# EFR32FG23B010F512IM48 register map
Vendor: Silicon Labs; Series: EFR32; File version: C
CPU: CM33 r0p4, little endian, MPU, FPU, DSP, VTOR, 4 interrupt priority bits, 8 SAU regions
Registers are 32-bit, read-write, reset 0x0 unless marked. A register's access mark holds for its fields unless they carry their own. Offsets are from the block's base; [hi:lo] are bit positions; {n}, {i} and the like mark numbered series.

## LCDRF_NS — LCDRF_NS Registers
Base 0x500C0000
Same registers: LCDRF_S 0x400C0000
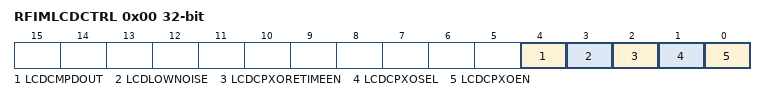
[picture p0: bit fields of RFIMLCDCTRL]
0x00 RFIMLCDCTRL
  [4] LCDCMPDOUT — LCD Comparator Dout
  [3] LCDLOWNOISE
    0=NORMAL (Normal operation); 1=SLOW (slows down slew rate to reduce RF interference at a cost of additional power consumption)
  [2] LCDCPXORETIMEEN — LCD Charge Pump XO Retime Enable
  [1] LCDCPXOSEL — LCD Charge Pump XO Select
    0=INTRCO (Internal LCD CP 10Mhz RC oscillator); 1=HFXODIV (HFXO divided 4 clock)
  [0] LCDCPXOEN — LCD Charge Pump XO Clock Enable

## LDMAXBAR_NS — LDMAXBAR_NS Registers
Base 0x50044000
Same registers: LDMAXBAR_S 0x40044000
0x00 IPVERSION ro reset 0x2
  [31:0] IPVERSION — IP Version ID
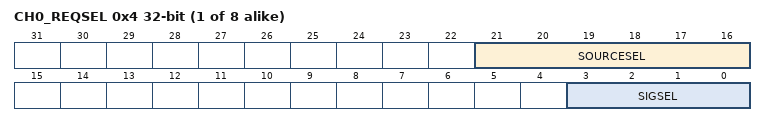
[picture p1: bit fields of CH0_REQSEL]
{0x4+4i} CH{i}_REQSEL (i=0..7)
  [21:16] SOURCESEL — Source Select
  [3:0] SIGSEL — Signal Select

## LFRCO_NS — LFRCO_NS Registers
Base 0x50024000
Same registers: LFRCO_S 0x40024000
0x00 IPVERSION ro — Contains the LFRCO ip version.
  [31:0] IPVERSION — IP version ID
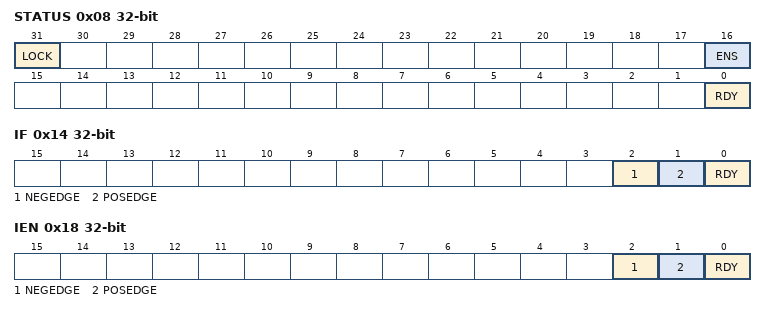
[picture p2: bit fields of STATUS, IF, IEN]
0x08 STATUS ro
  [31] LOCK — Lock Status
    0=UNLOCKED (Access to configuration registers not locked); 1=LOCKED (Access to configuration registers locked)
  [16] ENS — Enabled Status
  [0] RDY — Ready Status
0x0C CAL reset 0xA5 — Calibration register
  [7:0] FREQTRIM — Frequency Trim
0x14 IF — Interrupt flag register
  [2] NEGEDGE — Falling Edge Interrupt Flag
  [1] POSEDGE — Rising Edge Interrupt Flag
  [0] RDY — Ready Interrupt Flag
0x18 IEN — Interrupt enable register.
  [2] NEGEDGE — Falling Edge Interrupt Enable
  [1] POSEDGE — Rising Edge Interrupt Enable
  [0] RDY — Ready Interrupt Enable
0x1C SYNCBUSY ro — Synchronization busy register
  [0] CAL — CAL Busy
0x20 LOCK wo reset 0x2603 — Configuration lock register. Locks/unlocks access to cofiguration registers.
  [15:0] LOCKKEY
    0=LOCK (Lock Configuration Registers); 0x2603=UNLOCK (Unlock Configuaration Registers)

## LFXO_NS — LFXO_NS Registers
Base 0x50020000
Same registers: LFXO_S 0x40020000
0x00 IPVERSION ro
  [31:0] IPVERSION — IP Version ID
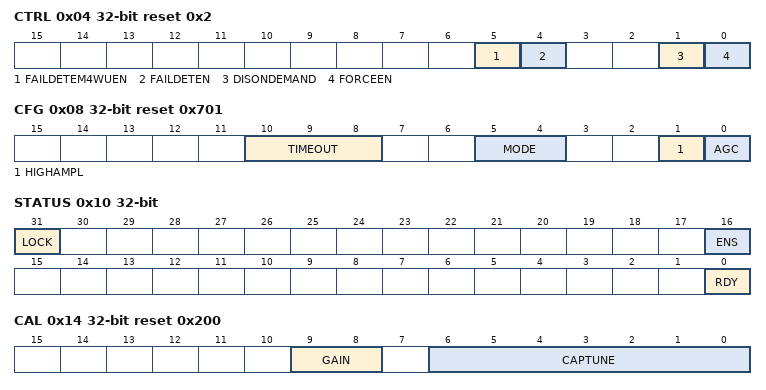
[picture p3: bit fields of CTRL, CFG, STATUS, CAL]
0x04 CTRL reset 0x2
  [5] FAILDETEM4WUEN — LFXO Failure Detection EM4WU Enable
  [4] FAILDETEN — LFXO Failure Detection Enable
  [1] DISONDEMAND — LFXO Disable On-demand requests
  [0] FORCEEN — LFXO Force Enable
0x08 CFG reset 0x701 — Do not write to this register unless the oscillator is forced off. The oscillator is forced off if DISONDEMAND is set and FORCEEN is cleared.
  [10:8] TIMEOUT — LFXO Start-up Delay
    0=CYCLES2 (Timeout period of 2 cycles); 1=CYCLES256 (Timeout period of 256 cycles); 2=CYCLES1K (Timeout period of 1024 cycles); 3=CYCLES2K (Timeout period of 2048 cycles); 4=CYCLES4K (Timeout period of 4096 cycles); 5=CYCLES8K (Timeout period of 8192 cycles); 6=CYCLES16K (Timeout period of 16384 cycles); 7=CYCLES32K (Timeout period of 32768 cycles)
  [5:4] MODE — LFXO Mode
    0=XTAL (A 32768Hz crystal should be connected to the LF crystal pads. Voltage must not exceed VDDIO.); 1=BUFEXTCLK (An external sine source with minimum amplitude 100mv (zero-to-peak) and maximum amplitude 500mV (zero-to-peak) should be connected in series with LFXTAL_I pin. Minimum voltage should be larger than ground and maximum voltage smaller than VDDIO. The sine source does not need to be ac coupled externally as it is ac couples inside LFXO. LFXTAL_O is free to be used as a general purpose GPIO.); 2=DIGEXTCLK (An external 32KHz CMOS clock should be provided on LFXTAL_I. LFXTAL_O is free to be used as a general purpose GPIO.)
  [1] HIGHAMPL — LFXO High Amplitude Enable
  [0] AGC — LFXO AGC Enable
0x10 STATUS ro
  [31] LOCK — LFXO Locked Status
    0=UNLOCKED (LFXO lockable registers are not locked); 1=LOCKED (LFXO lockable registers are locked)
  [16] ENS — LFXO Enable Status
  [0] RDY — LFXO Ready Status
0x14 CAL reset 0x200 — Do not write to this register unless CALBSY in SYNCBUSY register is low.
  [9:8] GAIN — LFXO Startup Gain
  [6:0] CAPTUNE — Internal Capacitance Tuning
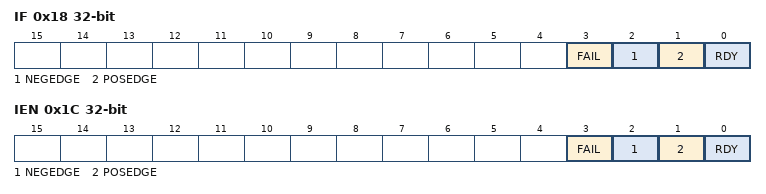
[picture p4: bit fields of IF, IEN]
0x18 IF
  [3] FAIL — LFXO Failure Interrupt Flag
  [2] NEGEDGE — Falling Edge Interrupt Flag
  [1] POSEDGE — Rising Edge Interrupt Flag
  [0] RDY — LFXO Ready Interrupt Flag
0x1C IEN
  [3] FAIL — LFXO Failure Interrupt Enable
  [2] NEGEDGE — Falling Edge Interrupt Enable
  [1] POSEDGE — Rising Edge Interrupt Enable
  [0] RDY — LFXO Ready Interrupt Enable
0x20 SYNCBUSY ro
  [0] CAL — LFXO Synchronization status
0x24 LOCK wo reset 0x1A20
  [15:0] LOCKKEY
    0x1A20=UNLOCK (Unlock LFXO lockable registers)
